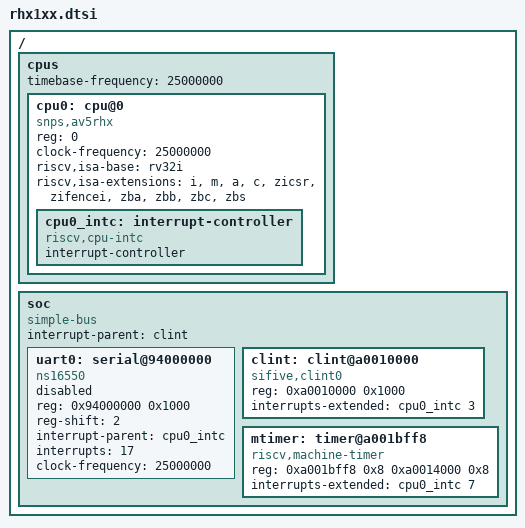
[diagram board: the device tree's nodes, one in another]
/ {
	#address-cells = <1>;
	#size-cells = <1>;

	cpus {
		timebase-frequency = <25000000>;
		#address-cells = <1>;
		#size-cells = <0>;

		cpu0: cpu@0 {
			compatible = "snps,av5rhx", "riscv";
			reg = <0>;
			device_type = "cpu";
			clock-frequency = <25000000>;
			riscv,isa-base = "rv32i";
			riscv,isa-extensions = "i", "m", "a", "c", "zicsr", "zifencei",
					       "zba", "zbb", "zbc", "zbs";

			cpu0_intc: interrupt-controller {
				compatible = "riscv,cpu-intc";
				interrupt-controller;
				#address-cells = <0>;
				#interrupt-cells = <1>;
			};
		};
	};

	soc {
		compatible = "simple-bus";
		ranges;
		interrupt-parent = <&clint>;
		#address-cells = <1>;
		#size-cells = <1>;

		uart0: serial@94000000 {
			compatible = "ns16550", "snps,dw-apb-uart";
			reg = <0x94000000 0x1000>;
			reg-shift = <2>;

			/* AIA interrupt controller is not currently implemented,
			 * so connect UART interrupt to 17th line as a stub to
			 * make build system and test framework happy.
			 */
			interrupt-parent = <&cpu0_intc>;
			interrupts = <17>;
			clock-frequency = <25000000>;
			status = "disabled";
		};

		clint: clint@a0010000 {
			compatible = "sifive,clint0";
			reg = <0xa0010000 0x1000>;
			interrupts-extended = <&cpu0_intc 3>;
		};

		mtimer: timer@a001bff8 {
			compatible = "riscv,machine-timer";
			reg = <0xa001bff8 0x8 0xa0014000 0x8>;
			interrupts-extended = <&cpu0_intc 7>;
			reg-names = "mtime", "mtimecmp";
		};
	};
};
